# MCU_NAVSS0_UDMASS_ECCAGGR0 register map
Vendor: Texas Instruments
Registers are 32-bit, access not given, reset 0x0 unless marked. A register's access mark holds for its fields unless they carry their own. Offsets are as the file gives them; [hi:lo] are bit positions; {n}, {i} and the like mark numbered series.

## MCU_NAVSS0_UDMASS_ECCAGGR0 (part 2 of 4)
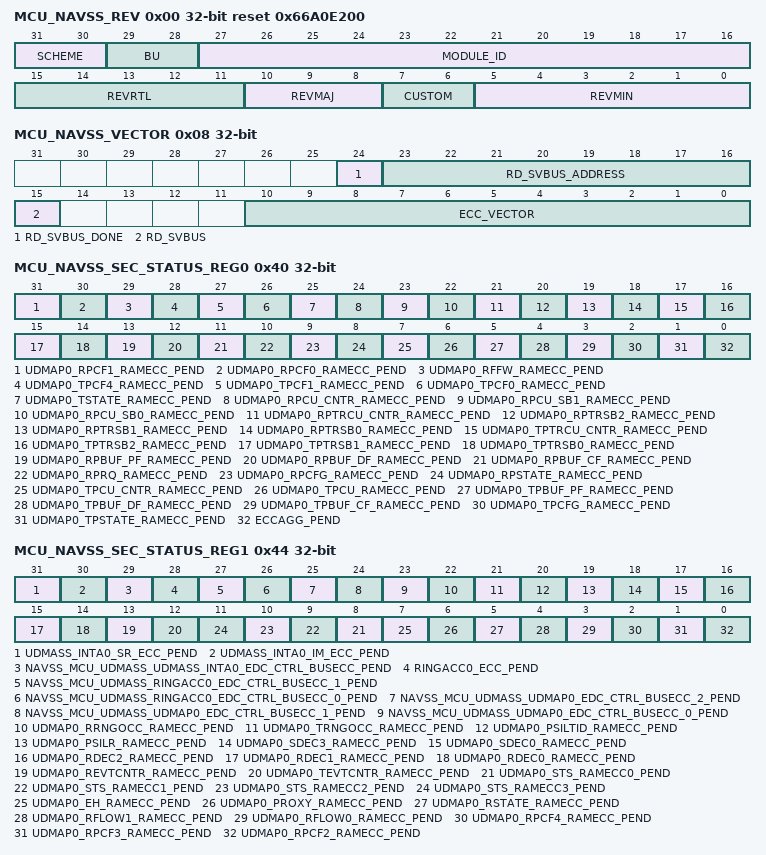
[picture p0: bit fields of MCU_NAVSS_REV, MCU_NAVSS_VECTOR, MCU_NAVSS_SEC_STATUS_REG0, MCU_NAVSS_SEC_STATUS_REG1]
0x00 MCU_NAVSS_REV ro reset 0x66A0E200 — Revision parameters
  [31:30] SCHEME
  [29:28] BU
  [27:16] MODULE_ID
  [15:11] REVRTL — RTL version
  [10:8] REVMAJ — Major version
  [7:6] CUSTOM — Custom version
  [5:0] REVMIN — Minor version
0x08 MCU_NAVSS_VECTOR — ECC Vector Register
  [24] RD_SVBUS_DONE — Status to indicate if read on serial VBUS is complete, write of any value will clear this bit. (access RW1C)
  [23:16] RD_SVBUS_ADDRESS rw — Read address
  [15] RD_SVBUS — Write 1 to trigger a read on the serial VBUS (access RW1S)
  [10:0] ECC_VECTOR rw — Value written to select the corresponding ECC RAM for control or status
0x0C MCU_NAVSS_STAT ro reset 0x78 — Misc Status
  [10:0] NUM_RAMS — Indicates the number of RAMS serviced by the ECC aggregator
0x3C MCU_NAVSS_SEC_EOI_REG — EOI Register The EOI register is used to re-trigger the pulse interrupt signal to ensure that any nested interrupt events are serviced. The software interrupt handler must write to the EOI register at the end of the current interrupt processing routine, so that new events can re-trigger the pulse interrupt signal again. For level interrupt signals the EOI register is not functional and must not be used.
  [0] EOI_WR — EOI Register (access RW1S)
0x40 MCU_NAVSS_SEC_STATUS_REG0 — Interrupt Status Register 0
  [31] UDMAP0_RPCF1_RAMECC_PEND — Interrupt Pending Status for udmap0_rpcf1_ramecc_pend (access RW1S)
  [30] UDMAP0_RPCF0_RAMECC_PEND — Interrupt Pending Status for udmap0_rpcf0_ramecc_pend (access RW1S)
  [29] UDMAP0_RFFW_RAMECC_PEND — Interrupt Pending Status for udmap0_rffw_ramecc_pend (access RW1S)
  [28] UDMAP0_TPCF4_RAMECC_PEND — Interrupt Pending Status for udmap0_tpcf4_ramecc_pend (access RW1S)
  [27] UDMAP0_TPCF1_RAMECC_PEND — Interrupt Pending Status for udmap0_tpcf1_ramecc_pend (access RW1S)
  [26] UDMAP0_TPCF0_RAMECC_PEND — Interrupt Pending Status for udmap0_tpcf0_ramecc_pend (access RW1S)
  [25] UDMAP0_TSTATE_RAMECC_PEND — Interrupt Pending Status for udmap0_tstate_ramecc_pend (access RW1S)
  [24] UDMAP0_RPCU_CNTR_RAMECC_PEND — Interrupt Pending Status for udmap0_rpcu_cntr_ramecc_pend (access RW1S)
  [23] UDMAP0_RPCU_SB1_RAMECC_PEND — Interrupt Pending Status for udmap0_rpcu_sb1_ramecc_pend (access RW1S)
  [22] UDMAP0_RPCU_SB0_RAMECC_PEND — Interrupt Pending Status for udmap0_rpcu_sb0_ramecc_pend (access RW1S)
  [21] UDMAP0_RPTRCU_CNTR_RAMECC_PEND — Interrupt Pending Status for udmap0_rptrcu_cntr_ramecc_pend (access RW1S)
  [20] UDMAP0_RPTRSB2_RAMECC_PEND — Interrupt Pending Status for udmap0_rptrsb2_ramecc_pend (access RW1S)
  [19] UDMAP0_RPTRSB1_RAMECC_PEND — Interrupt Pending Status for udmap0_rptrsb1_ramecc_pend (access RW1S)
  [18] UDMAP0_RPTRSB0_RAMECC_PEND — Interrupt Pending Status for udmap0_rptrsb0_ramecc_pend (access RW1S)
  [17] UDMAP0_TPTRCU_CNTR_RAMECC_PEND — Interrupt Pending Status for udmap0_tptrcu_cntr_ramecc_pend (access RW1S)
  [16] UDMAP0_TPTRSB2_RAMECC_PEND — Interrupt Pending Status for udmap0_tptrsb2_ramecc_pend (access RW1S)
  [15] UDMAP0_TPTRSB1_RAMECC_PEND — Interrupt Pending Status for udmap0_tptrsb1_ramecc_pend (access RW1S)
  [14] UDMAP0_TPTRSB0_RAMECC_PEND — Interrupt Pending Status for udmap0_tptrsb0_ramecc_pend (access RW1S)
  [13] UDMAP0_RPBUF_PF_RAMECC_PEND — Interrupt Pending Status for udmap0_rpbuf_pf_ramecc_pend (access RW1S)
  [12] UDMAP0_RPBUF_DF_RAMECC_PEND — Interrupt Pending Status for udmap0_rpbuf_df_ramecc_pend (access RW1S)
  [11] UDMAP0_RPBUF_CF_RAMECC_PEND — Interrupt Pending Status for udmap0_rpbuf_cf_ramecc_pend (access RW1S)
  [10] UDMAP0_RPRQ_RAMECC_PEND — Interrupt Pending Status for udmap0_rprq_ramecc_pend (access RW1S)
  [9] UDMAP0_RPCFG_RAMECC_PEND — Interrupt Pending Status for udmap0_rpcfg_ramecc_pend (access RW1S)
  [8] UDMAP0_RPSTATE_RAMECC_PEND — Interrupt Pending Status for udmap0_rpstate_ramecc_pend (access RW1S)
  [7] UDMAP0_TPCU_CNTR_RAMECC_PEND — Interrupt Pending Status for udmap0_tpcu_cntr_ramecc_pend (access RW1S)
  [6] UDMAP0_TPCU_RAMECC_PEND — Interrupt Pending Status for udmap0_tpcu_ramecc_pend (access RW1S)
  [5] UDMAP0_TPBUF_PF_RAMECC_PEND — Interrupt Pending Status for udmap0_tpbuf_pf_ramecc_pend (access RW1S)
  [4] UDMAP0_TPBUF_DF_RAMECC_PEND — Interrupt Pending Status for udmap0_tpbuf_df_ramecc_pend (access RW1S)
  [3] UDMAP0_TPBUF_CF_RAMECC_PEND — Interrupt Pending Status for udmap0_tpbuf_cf_ramecc_pend (access RW1S)
  [2] UDMAP0_TPCFG_RAMECC_PEND — Interrupt Pending Status for udmap0_tpcfg_ramecc_pend (access RW1S)
  [1] UDMAP0_TPSTATE_RAMECC_PEND — Interrupt Pending Status for udmap0_tpstate_ramecc_pend (access RW1S)
  [0] ECCAGG_PEND — Interrupt Pending Status for eccagg_pend (access RW1S)
0x44 MCU_NAVSS_SEC_STATUS_REG1 — Interrupt Status Register 1
  [31] UDMASS_INTA0_SR_ECC_PEND — Interrupt Pending Status for udmass_inta0_sr_ecc_pend (access RW1S)
  [30] UDMASS_INTA0_IM_ECC_PEND — Interrupt Pending Status for udmass_inta0_im_ecc_pend (access RW1S)
  [29] NAVSS_MCU_UDMASS_UDMASS_INTA0_EDC_CTRL_BUSECC_PEND — Interrupt Pending Status for navss_mcu_udmass_udmass_inta0_edc_ctrl_busecc_pend (access RW1S)
  [28] RINGACC0_ECC_PEND — Interrupt Pending Status for ringacc0_ecc_pend (access RW1S)
  [27] NAVSS_MCU_UDMASS_RINGACC0_EDC_CTRL_BUSECC_1_PEND — Interrupt Pending Status for navss_mcu_udmass_ringacc0_edc_ctrl_busecc_1_pend (access RW1S)
  [26] NAVSS_MCU_UDMASS_RINGACC0_EDC_CTRL_BUSECC_0_PEND — Interrupt Pending Status for navss_mcu_udmass_ringacc0_edc_ctrl_busecc_0_pend (access RW1S)
  [25] NAVSS_MCU_UDMASS_UDMAP0_EDC_CTRL_BUSECC_2_PEND — Interrupt Pending Status for navss_mcu_udmass_udmap0_edc_ctrl_busecc_2_pend (access RW1S)
  [24] NAVSS_MCU_UDMASS_UDMAP0_EDC_CTRL_BUSECC_1_PEND — Interrupt Pending Status for navss_mcu_udmass_udmap0_edc_ctrl_busecc_1_pend (access RW1S)
  [23] NAVSS_MCU_UDMASS_UDMAP0_EDC_CTRL_BUSECC_0_PEND — Interrupt Pending Status for navss_mcu_udmass_udmap0_edc_ctrl_busecc_0_pend (access RW1S)
  [22] UDMAP0_RRNGOCC_RAMECC_PEND — Interrupt Pending Status for udmap0_rrngocc_ramecc_pend (access RW1S)
  [21] UDMAP0_TRNGOCC_RAMECC_PEND — Interrupt Pending Status for udmap0_trngocc_ramecc_pend (access RW1S)
  [20] UDMAP0_PSILTID_RAMECC_PEND — Interrupt Pending Status for udmap0_psiltid_ramecc_pend (access RW1S)
  [19] UDMAP0_PSILR_RAMECC_PEND — Interrupt Pending Status for udmap0_psilr_ramecc_pend (access RW1S)
  [18] UDMAP0_SDEC3_RAMECC_PEND — Interrupt Pending Status for udmap0_sdec3_ramecc_pend (access RW1S)
  [17] UDMAP0_SDEC0_RAMECC_PEND — Interrupt Pending Status for udmap0_sdec0_ramecc_pend (access RW1S)
  [16] UDMAP0_RDEC2_RAMECC_PEND — Interrupt Pending Status for udmap0_rdec2_ramecc_pend (access RW1S)
  [15] UDMAP0_RDEC1_RAMECC_PEND — Interrupt Pending Status for udmap0_rdec1_ramecc_pend (access RW1S)
  [14] UDMAP0_RDEC0_RAMECC_PEND — Interrupt Pending Status for udmap0_rdec0_ramecc_pend (access RW1S)
  [13] UDMAP0_REVTCNTR_RAMECC_PEND — Interrupt Pending Status for udmap0_revtcntr_ramecc_pend (access RW1S)
  [12] UDMAP0_TEVTCNTR_RAMECC_PEND — Interrupt Pending Status for udmap0_tevtcntr_ramecc_pend (access RW1S)
  [n+8] UDMAP0_STS_RAMECC{n}_PEND (n=0..3) — Interrupt Pending Status for udmap0_sts_ramecc{n}_pend (access RW1S)
  [7] UDMAP0_EH_RAMECC_PEND — Interrupt Pending Status for udmap0_eh_ramecc_pend (access RW1S)
  [6] UDMAP0_PROXY_RAMECC_PEND — Interrupt Pending Status for udmap0_proxy_ramecc_pend (access RW1S)
  [5] UDMAP0_RSTATE_RAMECC_PEND — Interrupt Pending Status for udmap0_rstate_ramecc_pend (access RW1S)
  [4] UDMAP0_RFLOW1_RAMECC_PEND — Interrupt Pending Status for udmap0_rflow1_ramecc_pend (access RW1S)
  [3] UDMAP0_RFLOW0_RAMECC_PEND — Interrupt Pending Status for udmap0_rflow0_ramecc_pend (access RW1S)
  [2] UDMAP0_RPCF4_RAMECC_PEND — Interrupt Pending Status for udmap0_rpcf4_ramecc_pend (access RW1S)
  [1] UDMAP0_RPCF3_RAMECC_PEND — Interrupt Pending Status for udmap0_rpcf3_ramecc_pend (access RW1S)
  [0] UDMAP0_RPCF2_RAMECC_PEND — Interrupt Pending Status for udmap0_rpcf2_ramecc_pend (access RW1S)
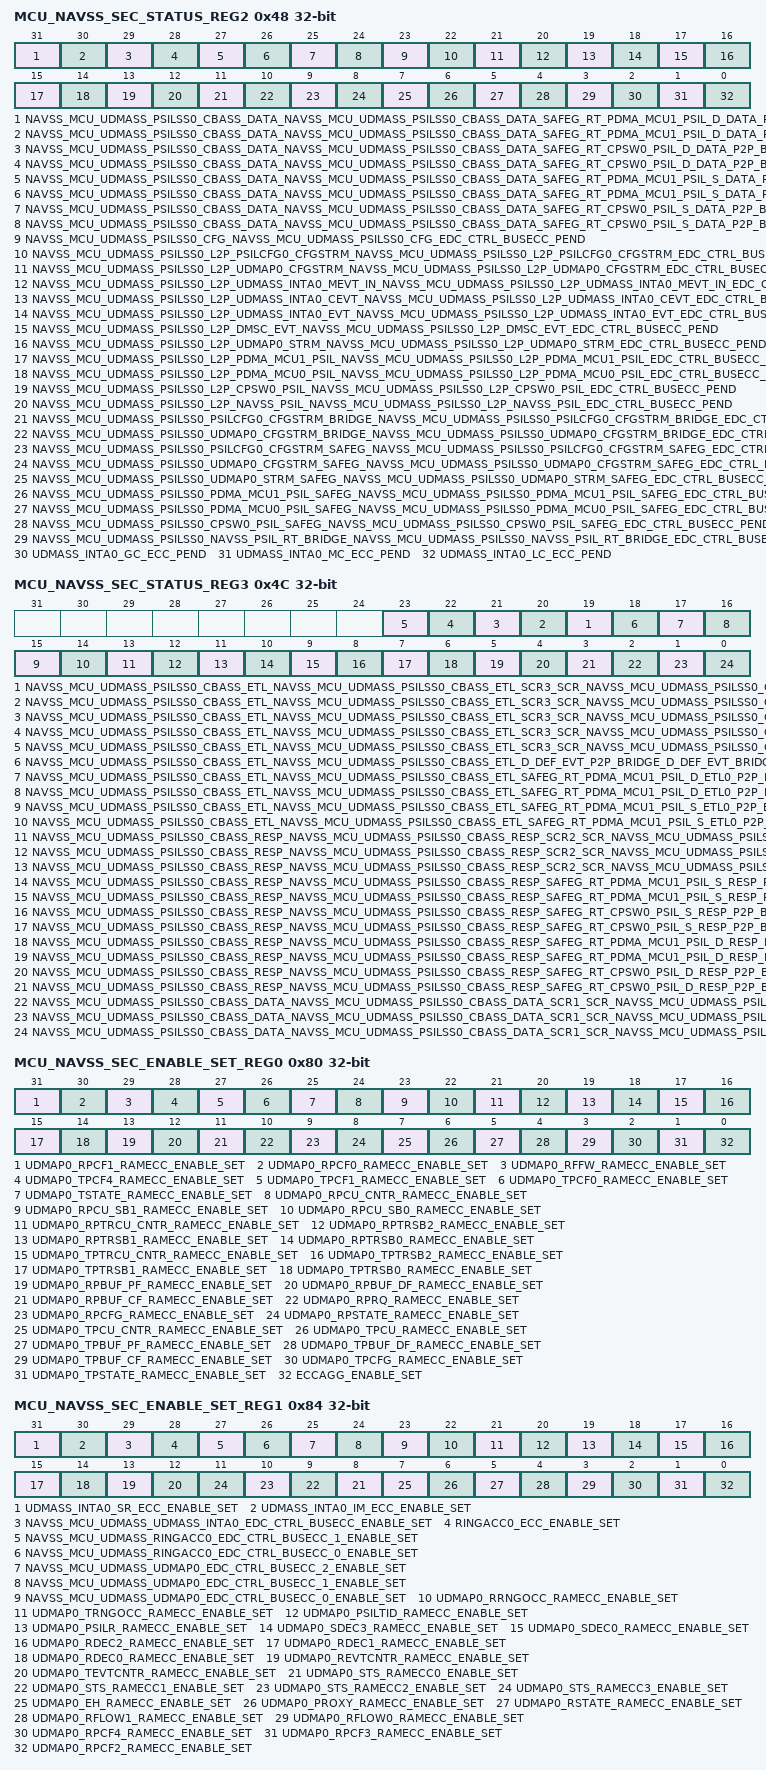
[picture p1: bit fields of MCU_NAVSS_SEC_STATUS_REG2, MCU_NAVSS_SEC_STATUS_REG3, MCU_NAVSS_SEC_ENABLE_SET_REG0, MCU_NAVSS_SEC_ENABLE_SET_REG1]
0x48 MCU_NAVSS_SEC_STATUS_REG2 — Interrupt Status Register 2
  [31] NAVSS_MCU_UDMASS_PSILSS0_CBASS_DATA_NAVSS_MCU_UDMASS_PSILSS0_CBASS_DATA_SAFEG_RT_PDMA_MCU1_PSIL_D_DATA_P2P_BRIDGE_SAFEG_RT_PDMA_MCU1_PSIL_D_DATA_BRIDGE_DST_BUSECC_PEND — Interrupt Pending Status for navss_mcu_udmass_psilss0_cbass_data_navss_mcu_udmass_psilss0_cbass_data_safeg_rt_pdma_mcu1_psil_d_data_p2p_bridge_safeg_rt_pdma_mcu1_psil_d_data_bridge_dst_busecc_pend (access RW1S)
  [30] NAVSS_MCU_UDMASS_PSILSS0_CBASS_DATA_NAVSS_MCU_UDMASS_PSILSS0_CBASS_DATA_SAFEG_RT_PDMA_MCU1_PSIL_D_DATA_P2P_BRIDGE_SAFEG_RT_PDMA_MCU1_PSIL_D_DATA_BRIDGE_SRC_BUSECC_PEND — Interrupt Pending Status for navss_mcu_udmass_psilss0_cbass_data_navss_mcu_udmass_psilss0_cbass_data_safeg_rt_pdma_mcu1_psil_d_data_p2p_bridge_safeg_rt_pdma_mcu1_psil_d_data_bridge_src_busecc_pend (access RW1S)
  [29] NAVSS_MCU_UDMASS_PSILSS0_CBASS_DATA_NAVSS_MCU_UDMASS_PSILSS0_CBASS_DATA_SAFEG_RT_CPSW0_PSIL_D_DATA_P2P_BRIDGE_SAFEG_RT_CPSW0_PSIL_D_DATA_BRIDGE_DST_BUSECC_PEND — Interrupt Pending Status for navss_mcu_udmass_psilss0_cbass_data_navss_mcu_udmass_psilss0_cbass_data_safeg_rt_cpsw0_psil_d_data_p2p_bridge_safeg_rt_cpsw0_psil_d_data_bridge_dst_busecc_pend (access RW1S)
  [28] NAVSS_MCU_UDMASS_PSILSS0_CBASS_DATA_NAVSS_MCU_UDMASS_PSILSS0_CBASS_DATA_SAFEG_RT_CPSW0_PSIL_D_DATA_P2P_BRIDGE_SAFEG_RT_CPSW0_PSIL_D_DATA_BRIDGE_SRC_BUSECC_PEND — Interrupt Pending Status for navss_mcu_udmass_psilss0_cbass_data_navss_mcu_udmass_psilss0_cbass_data_safeg_rt_cpsw0_psil_d_data_p2p_bridge_safeg_rt_cpsw0_psil_d_data_bridge_src_busecc_pend (access RW1S)
  [27] NAVSS_MCU_UDMASS_PSILSS0_CBASS_DATA_NAVSS_MCU_UDMASS_PSILSS0_CBASS_DATA_SAFEG_RT_PDMA_MCU1_PSIL_S_DATA_P2P_BRIDGE_SAFEG_RT_PDMA_MCU1_PSIL_S_DATA_BRIDGE_DST_BUSECC_PEND — Interrupt Pending Status for navss_mcu_udmass_psilss0_cbass_data_navss_mcu_udmass_psilss0_cbass_data_safeg_rt_pdma_mcu1_psil_s_data_p2p_bridge_safeg_rt_pdma_mcu1_psil_s_data_bridge_dst_busecc_pend (access RW1S)
  [26] NAVSS_MCU_UDMASS_PSILSS0_CBASS_DATA_NAVSS_MCU_UDMASS_PSILSS0_CBASS_DATA_SAFEG_RT_PDMA_MCU1_PSIL_S_DATA_P2P_BRIDGE_SAFEG_RT_PDMA_MCU1_PSIL_S_DATA_BRIDGE_SRC_BUSECC_PEND — Interrupt Pending Status for navss_mcu_udmass_psilss0_cbass_data_navss_mcu_udmass_psilss0_cbass_data_safeg_rt_pdma_mcu1_psil_s_data_p2p_bridge_safeg_rt_pdma_mcu1_psil_s_data_bridge_src_busecc_pend (access RW1S)
  [25] NAVSS_MCU_UDMASS_PSILSS0_CBASS_DATA_NAVSS_MCU_UDMASS_PSILSS0_CBASS_DATA_SAFEG_RT_CPSW0_PSIL_S_DATA_P2P_BRIDGE_SAFEG_RT_CPSW0_PSIL_S_DATA_BRIDGE_DST_BUSECC_PEND — Interrupt Pending Status for navss_mcu_udmass_psilss0_cbass_data_navss_mcu_udmass_psilss0_cbass_data_safeg_rt_cpsw0_psil_s_data_p2p_bridge_safeg_rt_cpsw0_psil_s_data_bridge_dst_busecc_pend (access RW1S)
  [24] NAVSS_MCU_UDMASS_PSILSS0_CBASS_DATA_NAVSS_MCU_UDMASS_PSILSS0_CBASS_DATA_SAFEG_RT_CPSW0_PSIL_S_DATA_P2P_BRIDGE_SAFEG_RT_CPSW0_PSIL_S_DATA_BRIDGE_SRC_BUSECC_PEND — Interrupt Pending Status for navss_mcu_udmass_psilss0_cbass_data_navss_mcu_udmass_psilss0_cbass_data_safeg_rt_cpsw0_psil_s_data_p2p_bridge_safeg_rt_cpsw0_psil_s_data_bridge_src_busecc_pend (access RW1S)
  [23] NAVSS_MCU_UDMASS_PSILSS0_CFG_NAVSS_MCU_UDMASS_PSILSS0_CFG_EDC_CTRL_BUSECC_PEND — Interrupt Pending Status for navss_mcu_udmass_psilss0_cfg_navss_mcu_udmass_psilss0_cfg_edc_ctrl_busecc_pend (access RW1S)
  [22] NAVSS_MCU_UDMASS_PSILSS0_L2P_PSILCFG0_CFGSTRM_NAVSS_MCU_UDMASS_PSILSS0_L2P_PSILCFG0_CFGSTRM_EDC_CTRL_BUSECC_PEND — Interrupt Pending Status for navss_mcu_udmass_psilss0_l2p_psilcfg0_cfgstrm_navss_mcu_udmass_psilss0_l2p_psilcfg0_cfgstrm_edc_ctrl_busecc_pend (access RW1S)
  [21] NAVSS_MCU_UDMASS_PSILSS0_L2P_UDMAP0_CFGSTRM_NAVSS_MCU_UDMASS_PSILSS0_L2P_UDMAP0_CFGSTRM_EDC_CTRL_BUSECC_PEND — Interrupt Pending Status for navss_mcu_udmass_psilss0_l2p_udmap0_cfgstrm_navss_mcu_udmass_psilss0_l2p_udmap0_cfgstrm_edc_ctrl_busecc_pend (access RW1S)
  [20] NAVSS_MCU_UDMASS_PSILSS0_L2P_UDMASS_INTA0_MEVT_IN_NAVSS_MCU_UDMASS_PSILSS0_L2P_UDMASS_INTA0_MEVT_IN_EDC_CTRL_BUSECC_PEND — Interrupt Pending Status for navss_mcu_udmass_psilss0_l2p_udmass_inta0_mevt_in_navss_mcu_udmass_psilss0_l2p_udmass_inta0_mevt_in_edc_ctrl_busecc_pend (access RW1S)
  [19] NAVSS_MCU_UDMASS_PSILSS0_L2P_UDMASS_INTA0_CEVT_NAVSS_MCU_UDMASS_PSILSS0_L2P_UDMASS_INTA0_CEVT_EDC_CTRL_BUSECC_PEND — Interrupt Pending Status for navss_mcu_udmass_psilss0_l2p_udmass_inta0_cevt_navss_mcu_udmass_psilss0_l2p_udmass_inta0_cevt_edc_ctrl_busecc_pend (access RW1S)
  [18] NAVSS_MCU_UDMASS_PSILSS0_L2P_UDMASS_INTA0_EVT_NAVSS_MCU_UDMASS_PSILSS0_L2P_UDMASS_INTA0_EVT_EDC_CTRL_BUSECC_PEND — Interrupt Pending Status for navss_mcu_udmass_psilss0_l2p_udmass_inta0_evt_navss_mcu_udmass_psilss0_l2p_udmass_inta0_evt_edc_ctrl_busecc_pend (access RW1S)
  [17] NAVSS_MCU_UDMASS_PSILSS0_L2P_DMSC_EVT_NAVSS_MCU_UDMASS_PSILSS0_L2P_DMSC_EVT_EDC_CTRL_BUSECC_PEND — Interrupt Pending Status for navss_mcu_udmass_psilss0_l2p_dmsc_evt_navss_mcu_udmass_psilss0_l2p_dmsc_evt_edc_ctrl_busecc_pend (access RW1S)
  [16] NAVSS_MCU_UDMASS_PSILSS0_L2P_UDMAP0_STRM_NAVSS_MCU_UDMASS_PSILSS0_L2P_UDMAP0_STRM_EDC_CTRL_BUSECC_PEND — Interrupt Pending Status for navss_mcu_udmass_psilss0_l2p_udmap0_strm_navss_mcu_udmass_psilss0_l2p_udmap0_strm_edc_ctrl_busecc_pend (access RW1S)
  [15] NAVSS_MCU_UDMASS_PSILSS0_L2P_PDMA_MCU1_PSIL_NAVSS_MCU_UDMASS_PSILSS0_L2P_PDMA_MCU1_PSIL_EDC_CTRL_BUSECC_PEND — Interrupt Pending Status for navss_mcu_udmass_psilss0_l2p_pdma_mcu1_psil_navss_mcu_udmass_psilss0_l2p_pdma_mcu1_psil_edc_ctrl_busecc_pend (access RW1S)
  [14] NAVSS_MCU_UDMASS_PSILSS0_L2P_PDMA_MCU0_PSIL_NAVSS_MCU_UDMASS_PSILSS0_L2P_PDMA_MCU0_PSIL_EDC_CTRL_BUSECC_PEND — Interrupt Pending Status for navss_mcu_udmass_psilss0_l2p_pdma_mcu0_psil_navss_mcu_udmass_psilss0_l2p_pdma_mcu0_psil_edc_ctrl_busecc_pend (access RW1S)
  [13] NAVSS_MCU_UDMASS_PSILSS0_L2P_CPSW0_PSIL_NAVSS_MCU_UDMASS_PSILSS0_L2P_CPSW0_PSIL_EDC_CTRL_BUSECC_PEND — Interrupt Pending Status for navss_mcu_udmass_psilss0_l2p_cpsw0_psil_navss_mcu_udmass_psilss0_l2p_cpsw0_psil_edc_ctrl_busecc_pend (access RW1S)
  [12] NAVSS_MCU_UDMASS_PSILSS0_L2P_NAVSS_PSIL_NAVSS_MCU_UDMASS_PSILSS0_L2P_NAVSS_PSIL_EDC_CTRL_BUSECC_PEND — Interrupt Pending Status for navss_mcu_udmass_psilss0_l2p_navss_psil_navss_mcu_udmass_psilss0_l2p_navss_psil_edc_ctrl_busecc_pend (access RW1S)
  [11] NAVSS_MCU_UDMASS_PSILSS0_PSILCFG0_CFGSTRM_BRIDGE_NAVSS_MCU_UDMASS_PSILSS0_PSILCFG0_CFGSTRM_BRIDGE_EDC_CTRL_BUSECC_PEND — Interrupt Pending Status for navss_mcu_udmass_psilss0_psilcfg0_cfgstrm_bridge_navss_mcu_udmass_psilss0_psilcfg0_cfgstrm_bridge_edc_ctrl_busecc_pend (access RW1S)
  [10] NAVSS_MCU_UDMASS_PSILSS0_UDMAP0_CFGSTRM_BRIDGE_NAVSS_MCU_UDMASS_PSILSS0_UDMAP0_CFGSTRM_BRIDGE_EDC_CTRL_BUSECC_PEND — Interrupt Pending Status for navss_mcu_udmass_psilss0_udmap0_cfgstrm_bridge_navss_mcu_udmass_psilss0_udmap0_cfgstrm_bridge_edc_ctrl_busecc_pend (access RW1S)
  [9] NAVSS_MCU_UDMASS_PSILSS0_PSILCFG0_CFGSTRM_SAFEG_NAVSS_MCU_UDMASS_PSILSS0_PSILCFG0_CFGSTRM_SAFEG_EDC_CTRL_BUSECC_PEND — Interrupt Pending Status for navss_mcu_udmass_psilss0_psilcfg0_cfgstrm_safeg_navss_mcu_udmass_psilss0_psilcfg0_cfgstrm_safeg_edc_ctrl_busecc_pend (access RW1S)
  [8] NAVSS_MCU_UDMASS_PSILSS0_UDMAP0_CFGSTRM_SAFEG_NAVSS_MCU_UDMASS_PSILSS0_UDMAP0_CFGSTRM_SAFEG_EDC_CTRL_BUSECC_PEND — Interrupt Pending Status for navss_mcu_udmass_psilss0_udmap0_cfgstrm_safeg_navss_mcu_udmass_psilss0_udmap0_cfgstrm_safeg_edc_ctrl_busecc_pend (access RW1S)
  [7] NAVSS_MCU_UDMASS_PSILSS0_UDMAP0_STRM_SAFEG_NAVSS_MCU_UDMASS_PSILSS0_UDMAP0_STRM_SAFEG_EDC_CTRL_BUSECC_PEND — Interrupt Pending Status for navss_mcu_udmass_psilss0_udmap0_strm_safeg_navss_mcu_udmass_psilss0_udmap0_strm_safeg_edc_ctrl_busecc_pend (access RW1S)
  [6] NAVSS_MCU_UDMASS_PSILSS0_PDMA_MCU1_PSIL_SAFEG_NAVSS_MCU_UDMASS_PSILSS0_PDMA_MCU1_PSIL_SAFEG_EDC_CTRL_BUSECC_PEND — Interrupt Pending Status for navss_mcu_udmass_psilss0_pdma_mcu1_psil_safeg_navss_mcu_udmass_psilss0_pdma_mcu1_psil_safeg_edc_ctrl_busecc_pend (access RW1S)
  [5] NAVSS_MCU_UDMASS_PSILSS0_PDMA_MCU0_PSIL_SAFEG_NAVSS_MCU_UDMASS_PSILSS0_PDMA_MCU0_PSIL_SAFEG_EDC_CTRL_BUSECC_PEND — Interrupt Pending Status for navss_mcu_udmass_psilss0_pdma_mcu0_psil_safeg_navss_mcu_udmass_psilss0_pdma_mcu0_psil_safeg_edc_ctrl_busecc_pend (access RW1S)
  [4] NAVSS_MCU_UDMASS_PSILSS0_CPSW0_PSIL_SAFEG_NAVSS_MCU_UDMASS_PSILSS0_CPSW0_PSIL_SAFEG_EDC_CTRL_BUSECC_PEND — Interrupt Pending Status for navss_mcu_udmass_psilss0_cpsw0_psil_safeg_navss_mcu_udmass_psilss0_cpsw0_psil_safeg_edc_ctrl_busecc_pend (access RW1S)
  [3] NAVSS_MCU_UDMASS_PSILSS0_NAVSS_PSIL_RT_BRIDGE_NAVSS_MCU_UDMASS_PSILSS0_NAVSS_PSIL_RT_BRIDGE_EDC_CTRL_BUSECC_PEND — Interrupt Pending Status for navss_mcu_udmass_psilss0_navss_psil_rt_bridge_navss_mcu_udmass_psilss0_navss_psil_rt_bridge_edc_ctrl_busecc_pend (access RW1S)
  [2] UDMASS_INTA0_GC_ECC_PEND — Interrupt Pending Status for udmass_inta0_gc_ecc_pend (access RW1S)
  [1] UDMASS_INTA0_MC_ECC_PEND — Interrupt Pending Status for udmass_inta0_mc_ecc_pend (access RW1S)
  [0] UDMASS_INTA0_LC_ECC_PEND — Interrupt Pending Status for udmass_inta0_lc_ecc_pend (access RW1S)
0x4C MCU_NAVSS_SEC_STATUS_REG3 — Interrupt Status Register 3
  [n+19] NAVSS_MCU_UDMASS_PSILSS0_CBASS_ETL_NAVSS_MCU_UDMASS_PSILSS0_CBASS_ETL_SCR3_SCR_NAVSS_MCU_UDMASS_PSILSS0_CBASS_ETL_SCR3_SCR_EDC_CTRL_BUSECC_{n}_PEND (n=0..4) — Interrupt Pending Status for navss_mcu_udmass_psilss0_cbass_etl_navss_mcu_udmass_psilss0_cbass_etl_scr3_scr_navss_mcu_udmass_psilss0_cbass_etl_scr3_scr_edc_ctrl_busecc_{n}_pend (access RW1S)
  [18] NAVSS_MCU_UDMASS_PSILSS0_CBASS_ETL_NAVSS_MCU_UDMASS_PSILSS0_CBASS_ETL_D_DEF_EVT_P2P_BRIDGE_D_DEF_EVT_BRIDGE_BUSECC_PEND — Interrupt Pending Status for navss_mcu_udmass_psilss0_cbass_etl_navss_mcu_udmass_psilss0_cbass_etl_d_def_evt_p2p_bridge_d_def_evt_bridge_busecc_pend (access RW1S)
  [17] NAVSS_MCU_UDMASS_PSILSS0_CBASS_ETL_NAVSS_MCU_UDMASS_PSILSS0_CBASS_ETL_SAFEG_RT_PDMA_MCU1_PSIL_D_ETL0_P2P_BRIDGE_SAFEG_RT_PDMA_MCU1_PSIL_D_ETL0_BRIDGE_DST_BUSECC_PEND — Interrupt Pending Status for navss_mcu_udmass_psilss0_cbass_etl_navss_mcu_udmass_psilss0_cbass_etl_safeg_rt_pdma_mcu1_psil_d_etl0_p2p_bridge_safeg_rt_pdma_mcu1_psil_d_etl0_bridge_dst_busecc_pend (access RW1S)
  [16] NAVSS_MCU_UDMASS_PSILSS0_CBASS_ETL_NAVSS_MCU_UDMASS_PSILSS0_CBASS_ETL_SAFEG_RT_PDMA_MCU1_PSIL_D_ETL0_P2P_BRIDGE_SAFEG_RT_PDMA_MCU1_PSIL_D_ETL0_BRIDGE_SRC_BUSECC_PEND — Interrupt Pending Status for navss_mcu_udmass_psilss0_cbass_etl_navss_mcu_udmass_psilss0_cbass_etl_safeg_rt_pdma_mcu1_psil_d_etl0_p2p_bridge_safeg_rt_pdma_mcu1_psil_d_etl0_bridge_src_busecc_pend (access RW1S)
  [15] NAVSS_MCU_UDMASS_PSILSS0_CBASS_ETL_NAVSS_MCU_UDMASS_PSILSS0_CBASS_ETL_SAFEG_RT_PDMA_MCU1_PSIL_S_ETL0_P2P_BRIDGE_SAFEG_RT_PDMA_MCU1_PSIL_S_ETL0_BRIDGE_DST_BUSECC_PEND — Interrupt Pending Status for navss_mcu_udmass_psilss0_cbass_etl_navss_mcu_udmass_psilss0_cbass_etl_safeg_rt_pdma_mcu1_psil_s_etl0_p2p_bridge_safeg_rt_pdma_mcu1_psil_s_etl0_bridge_dst_busecc_pend (access RW1S)
  [14] NAVSS_MCU_UDMASS_PSILSS0_CBASS_ETL_NAVSS_MCU_UDMASS_PSILSS0_CBASS_ETL_SAFEG_RT_PDMA_MCU1_PSIL_S_ETL0_P2P_BRIDGE_SAFEG_RT_PDMA_MCU1_PSIL_S_ETL0_BRIDGE_SRC_BUSECC_PEND — Interrupt Pending Status for navss_mcu_udmass_psilss0_cbass_etl_navss_mcu_udmass_psilss0_cbass_etl_safeg_rt_pdma_mcu1_psil_s_etl0_p2p_bridge_safeg_rt_pdma_mcu1_psil_s_etl0_bridge_src_busecc_pend (access RW1S)
  [13] NAVSS_MCU_UDMASS_PSILSS0_CBASS_RESP_NAVSS_MCU_UDMASS_PSILSS0_CBASS_RESP_SCR2_SCR_NAVSS_MCU_UDMASS_PSILSS0_CBASS_RESP_SCR2_SCR_EDC_CTRL_BUSECC_2_PEND — Interrupt Pending Status for navss_mcu_udmass_psilss0_cbass_resp_navss_mcu_udmass_psilss0_cbass_resp_scr2_scr_navss_mcu_udmass_psilss0_cbass_resp_scr2_scr_edc_ctrl_busecc_2_pend (access RW1S)
  [12] NAVSS_MCU_UDMASS_PSILSS0_CBASS_RESP_NAVSS_MCU_UDMASS_PSILSS0_CBASS_RESP_SCR2_SCR_NAVSS_MCU_UDMASS_PSILSS0_CBASS_RESP_SCR2_SCR_EDC_CTRL_BUSECC_1_PEND — Interrupt Pending Status for navss_mcu_udmass_psilss0_cbass_resp_navss_mcu_udmass_psilss0_cbass_resp_scr2_scr_navss_mcu_udmass_psilss0_cbass_resp_scr2_scr_edc_ctrl_busecc_1_pend (access RW1S)
  [11] NAVSS_MCU_UDMASS_PSILSS0_CBASS_RESP_NAVSS_MCU_UDMASS_PSILSS0_CBASS_RESP_SCR2_SCR_NAVSS_MCU_UDMASS_PSILSS0_CBASS_RESP_SCR2_SCR_EDC_CTRL_BUSECC_0_PEND — Interrupt Pending Status for navss_mcu_udmass_psilss0_cbass_resp_navss_mcu_udmass_psilss0_cbass_resp_scr2_scr_navss_mcu_udmass_psilss0_cbass_resp_scr2_scr_edc_ctrl_busecc_0_pend (access RW1S)
  [10] NAVSS_MCU_UDMASS_PSILSS0_CBASS_RESP_NAVSS_MCU_UDMASS_PSILSS0_CBASS_RESP_SAFEG_RT_PDMA_MCU1_PSIL_S_RESP_P2P_BRIDGE_SAFEG_RT_PDMA_MCU1_PSIL_S_RESP_BRIDGE_DST_BUSECC_PEND — Interrupt Pending Status for navss_mcu_udmass_psilss0_cbass_resp_navss_mcu_udmass_psilss0_cbass_resp_safeg_rt_pdma_mcu1_psil_s_resp_p2p_bridge_safeg_rt_pdma_mcu1_psil_s_resp_bridge_dst_busecc_pend (access RW1S)
  [9] NAVSS_MCU_UDMASS_PSILSS0_CBASS_RESP_NAVSS_MCU_UDMASS_PSILSS0_CBASS_RESP_SAFEG_RT_PDMA_MCU1_PSIL_S_RESP_P2P_BRIDGE_SAFEG_RT_PDMA_MCU1_PSIL_S_RESP_BRIDGE_SRC_BUSECC_PEND — Interrupt Pending Status for navss_mcu_udmass_psilss0_cbass_resp_navss_mcu_udmass_psilss0_cbass_resp_safeg_rt_pdma_mcu1_psil_s_resp_p2p_bridge_safeg_rt_pdma_mcu1_psil_s_resp_bridge_src_busecc_pend (access RW1S)
  [8] NAVSS_MCU_UDMASS_PSILSS0_CBASS_RESP_NAVSS_MCU_UDMASS_PSILSS0_CBASS_RESP_SAFEG_RT_CPSW0_PSIL_S_RESP_P2P_BRIDGE_SAFEG_RT_CPSW0_PSIL_S_RESP_BRIDGE_DST_BUSECC_PEND — Interrupt Pending Status for navss_mcu_udmass_psilss0_cbass_resp_navss_mcu_udmass_psilss0_cbass_resp_safeg_rt_cpsw0_psil_s_resp_p2p_bridge_safeg_rt_cpsw0_psil_s_resp_bridge_dst_busecc_pend (access RW1S)
  [7] NAVSS_MCU_UDMASS_PSILSS0_CBASS_RESP_NAVSS_MCU_UDMASS_PSILSS0_CBASS_RESP_SAFEG_RT_CPSW0_PSIL_S_RESP_P2P_BRIDGE_SAFEG_RT_CPSW0_PSIL_S_RESP_BRIDGE_SRC_BUSECC_PEND — Interrupt Pending Status for navss_mcu_udmass_psilss0_cbass_resp_navss_mcu_udmass_psilss0_cbass_resp_safeg_rt_cpsw0_psil_s_resp_p2p_bridge_safeg_rt_cpsw0_psil_s_resp_bridge_src_busecc_pend (access RW1S)
  [6] NAVSS_MCU_UDMASS_PSILSS0_CBASS_RESP_NAVSS_MCU_UDMASS_PSILSS0_CBASS_RESP_SAFEG_RT_PDMA_MCU1_PSIL_D_RESP_P2P_BRIDGE_SAFEG_RT_PDMA_MCU1_PSIL_D_RESP_BRIDGE_DST_BUSECC_PEND — Interrupt Pending Status for navss_mcu_udmass_psilss0_cbass_resp_navss_mcu_udmass_psilss0_cbass_resp_safeg_rt_pdma_mcu1_psil_d_resp_p2p_bridge_safeg_rt_pdma_mcu1_psil_d_resp_bridge_dst_busecc_pend (access RW1S)
  [5] NAVSS_MCU_UDMASS_PSILSS0_CBASS_RESP_NAVSS_MCU_UDMASS_PSILSS0_CBASS_RESP_SAFEG_RT_PDMA_MCU1_PSIL_D_RESP_P2P_BRIDGE_SAFEG_RT_PDMA_MCU1_PSIL_D_RESP_BRIDGE_SRC_BUSECC_PEND — Interrupt Pending Status for navss_mcu_udmass_psilss0_cbass_resp_navss_mcu_udmass_psilss0_cbass_resp_safeg_rt_pdma_mcu1_psil_d_resp_p2p_bridge_safeg_rt_pdma_mcu1_psil_d_resp_bridge_src_busecc_pend (access RW1S)
  [4] NAVSS_MCU_UDMASS_PSILSS0_CBASS_RESP_NAVSS_MCU_UDMASS_PSILSS0_CBASS_RESP_SAFEG_RT_CPSW0_PSIL_D_RESP_P2P_BRIDGE_SAFEG_RT_CPSW0_PSIL_D_RESP_BRIDGE_DST_BUSECC_PEND — Interrupt Pending Status for navss_mcu_udmass_psilss0_cbass_resp_navss_mcu_udmass_psilss0_cbass_resp_safeg_rt_cpsw0_psil_d_resp_p2p_bridge_safeg_rt_cpsw0_psil_d_resp_bridge_dst_busecc_pend (access RW1S)
  [3] NAVSS_MCU_UDMASS_PSILSS0_CBASS_RESP_NAVSS_MCU_UDMASS_PSILSS0_CBASS_RESP_SAFEG_RT_CPSW0_PSIL_D_RESP_P2P_BRIDGE_SAFEG_RT_CPSW0_PSIL_D_RESP_BRIDGE_SRC_BUSECC_PEND — Interrupt Pending Status for navss_mcu_udmass_psilss0_cbass_resp_navss_mcu_udmass_psilss0_cbass_resp_safeg_rt_cpsw0_psil_d_resp_p2p_bridge_safeg_rt_cpsw0_psil_d_resp_bridge_src_busecc_pend (access RW1S)
  [2] NAVSS_MCU_UDMASS_PSILSS0_CBASS_DATA_NAVSS_MCU_UDMASS_PSILSS0_CBASS_DATA_SCR1_SCR_NAVSS_MCU_UDMASS_PSILSS0_CBASS_DATA_SCR1_SCR_EDC_CTRL_BUSECC_2_PEND — Interrupt Pending Status for navss_mcu_udmass_psilss0_cbass_data_navss_mcu_udmass_psilss0_cbass_data_scr1_scr_navss_mcu_udmass_psilss0_cbass_data_scr1_scr_edc_ctrl_busecc_2_pend (access RW1S)
  [1] NAVSS_MCU_UDMASS_PSILSS0_CBASS_DATA_NAVSS_MCU_UDMASS_PSILSS0_CBASS_DATA_SCR1_SCR_NAVSS_MCU_UDMASS_PSILSS0_CBASS_DATA_SCR1_SCR_EDC_CTRL_BUSECC_1_PEND — Interrupt Pending Status for navss_mcu_udmass_psilss0_cbass_data_navss_mcu_udmass_psilss0_cbass_data_scr1_scr_navss_mcu_udmass_psilss0_cbass_data_scr1_scr_edc_ctrl_busecc_1_pend (access RW1S)
  [0] NAVSS_MCU_UDMASS_PSILSS0_CBASS_DATA_NAVSS_MCU_UDMASS_PSILSS0_CBASS_DATA_SCR1_SCR_NAVSS_MCU_UDMASS_PSILSS0_CBASS_DATA_SCR1_SCR_EDC_CTRL_BUSECC_0_PEND — Interrupt Pending Status for navss_mcu_udmass_psilss0_cbass_data_navss_mcu_udmass_psilss0_cbass_data_scr1_scr_navss_mcu_udmass_psilss0_cbass_data_scr1_scr_edc_ctrl_busecc_0_pend (access RW1S)
0x80 MCU_NAVSS_SEC_ENABLE_SET_REG0 — Interrupt Enable Set Register 0
  [31] UDMAP0_RPCF1_RAMECC_ENABLE_SET — Interrupt Enable Set Register for udmap0_rpcf1_ramecc_pend (access RW1S)
  [30] UDMAP0_RPCF0_RAMECC_ENABLE_SET — Interrupt Enable Set Register for udmap0_rpcf0_ramecc_pend (access RW1S)
  [29] UDMAP0_RFFW_RAMECC_ENABLE_SET — Interrupt Enable Set Register for udmap0_rffw_ramecc_pend (access RW1S)
  [28] UDMAP0_TPCF4_RAMECC_ENABLE_SET — Interrupt Enable Set Register for udmap0_tpcf4_ramecc_pend (access RW1S)
  [27] UDMAP0_TPCF1_RAMECC_ENABLE_SET — Interrupt Enable Set Register for udmap0_tpcf1_ramecc_pend (access RW1S)
  [26] UDMAP0_TPCF0_RAMECC_ENABLE_SET — Interrupt Enable Set Register for udmap0_tpcf0_ramecc_pend (access RW1S)
  [25] UDMAP0_TSTATE_RAMECC_ENABLE_SET — Interrupt Enable Set Register for udmap0_tstate_ramecc_pend (access RW1S)
  [24] UDMAP0_RPCU_CNTR_RAMECC_ENABLE_SET — Interrupt Enable Set Register for udmap0_rpcu_cntr_ramecc_pend (access RW1S)
  [23] UDMAP0_RPCU_SB1_RAMECC_ENABLE_SET — Interrupt Enable Set Register for udmap0_rpcu_sb1_ramecc_pend (access RW1S)
  [22] UDMAP0_RPCU_SB0_RAMECC_ENABLE_SET — Interrupt Enable Set Register for udmap0_rpcu_sb0_ramecc_pend (access RW1S)
  [21] UDMAP0_RPTRCU_CNTR_RAMECC_ENABLE_SET — Interrupt Enable Set Register for udmap0_rptrcu_cntr_ramecc_pend (access RW1S)
  [20] UDMAP0_RPTRSB2_RAMECC_ENABLE_SET — Interrupt Enable Set Register for udmap0_rptrsb2_ramecc_pend (access RW1S)
  [19] UDMAP0_RPTRSB1_RAMECC_ENABLE_SET — Interrupt Enable Set Register for udmap0_rptrsb1_ramecc_pend (access RW1S)
  [18] UDMAP0_RPTRSB0_RAMECC_ENABLE_SET — Interrupt Enable Set Register for udmap0_rptrsb0_ramecc_pend (access RW1S)
  [17] UDMAP0_TPTRCU_CNTR_RAMECC_ENABLE_SET — Interrupt Enable Set Register for udmap0_tptrcu_cntr_ramecc_pend (access RW1S)
  [16] UDMAP0_TPTRSB2_RAMECC_ENABLE_SET — Interrupt Enable Set Register for udmap0_tptrsb2_ramecc_pend (access RW1S)
  [15] UDMAP0_TPTRSB1_RAMECC_ENABLE_SET — Interrupt Enable Set Register for udmap0_tptrsb1_ramecc_pend (access RW1S)
  [14] UDMAP0_TPTRSB0_RAMECC_ENABLE_SET — Interrupt Enable Set Register for udmap0_tptrsb0_ramecc_pend (access RW1S)
  [13] UDMAP0_RPBUF_PF_RAMECC_ENABLE_SET — Interrupt Enable Set Register for udmap0_rpbuf_pf_ramecc_pend (access RW1S)
  [12] UDMAP0_RPBUF_DF_RAMECC_ENABLE_SET — Interrupt Enable Set Register for udmap0_rpbuf_df_ramecc_pend (access RW1S)
  [11] UDMAP0_RPBUF_CF_RAMECC_ENABLE_SET — Interrupt Enable Set Register for udmap0_rpbuf_cf_ramecc_pend (access RW1S)
  [10] UDMAP0_RPRQ_RAMECC_ENABLE_SET — Interrupt Enable Set Register for udmap0_rprq_ramecc_pend (access RW1S)
  [9] UDMAP0_RPCFG_RAMECC_ENABLE_SET — Interrupt Enable Set Register for udmap0_rpcfg_ramecc_pend (access RW1S)
  [8] UDMAP0_RPSTATE_RAMECC_ENABLE_SET — Interrupt Enable Set Register for udmap0_rpstate_ramecc_pend (access RW1S)
  [7] UDMAP0_TPCU_CNTR_RAMECC_ENABLE_SET — Interrupt Enable Set Register for udmap0_tpcu_cntr_ramecc_pend (access RW1S)
  [6] UDMAP0_TPCU_RAMECC_ENABLE_SET — Interrupt Enable Set Register for udmap0_tpcu_ramecc_pend (access RW1S)
  [5] UDMAP0_TPBUF_PF_RAMECC_ENABLE_SET — Interrupt Enable Set Register for udmap0_tpbuf_pf_ramecc_pend (access RW1S)
  [4] UDMAP0_TPBUF_DF_RAMECC_ENABLE_SET — Interrupt Enable Set Register for udmap0_tpbuf_df_ramecc_pend (access RW1S)
  [3] UDMAP0_TPBUF_CF_RAMECC_ENABLE_SET — Interrupt Enable Set Register for udmap0_tpbuf_cf_ramecc_pend (access RW1S)
  [2] UDMAP0_TPCFG_RAMECC_ENABLE_SET — Interrupt Enable Set Register for udmap0_tpcfg_ramecc_pend (access RW1S)
  [1] UDMAP0_TPSTATE_RAMECC_ENABLE_SET — Interrupt Enable Set Register for udmap0_tpstate_ramecc_pend (access RW1S)
  [0] ECCAGG_ENABLE_SET — Interrupt Enable Set Register for eccagg_pend (access RW1S)
0x84 MCU_NAVSS_SEC_ENABLE_SET_REG1 — Interrupt Enable Set Register 1
  [31] UDMASS_INTA0_SR_ECC_ENABLE_SET — Interrupt Enable Set Register for udmass_inta0_sr_ecc_pend (access RW1S)
  [30] UDMASS_INTA0_IM_ECC_ENABLE_SET — Interrupt Enable Set Register for udmass_inta0_im_ecc_pend (access RW1S)
  [29] NAVSS_MCU_UDMASS_UDMASS_INTA0_EDC_CTRL_BUSECC_ENABLE_SET — Interrupt Enable Set Register for navss_mcu_udmass_udmass_inta0_edc_ctrl_busecc_pend (access RW1S)
  [28] RINGACC0_ECC_ENABLE_SET — Interrupt Enable Set Register for ringacc0_ecc_pend (access RW1S)
  [27] NAVSS_MCU_UDMASS_RINGACC0_EDC_CTRL_BUSECC_1_ENABLE_SET — Interrupt Enable Set Register for navss_mcu_udmass_ringacc0_edc_ctrl_busecc_1_pend (access RW1S)
  [26] NAVSS_MCU_UDMASS_RINGACC0_EDC_CTRL_BUSECC_0_ENABLE_SET — Interrupt Enable Set Register for navss_mcu_udmass_ringacc0_edc_ctrl_busecc_0_pend (access RW1S)
  [25] NAVSS_MCU_UDMASS_UDMAP0_EDC_CTRL_BUSECC_2_ENABLE_SET — Interrupt Enable Set Register for navss_mcu_udmass_udmap0_edc_ctrl_busecc_2_pend (access RW1S)
  [24] NAVSS_MCU_UDMASS_UDMAP0_EDC_CTRL_BUSECC_1_ENABLE_SET — Interrupt Enable Set Register for navss_mcu_udmass_udmap0_edc_ctrl_busecc_1_pend (access RW1S)
  [23] NAVSS_MCU_UDMASS_UDMAP0_EDC_CTRL_BUSECC_0_ENABLE_SET — Interrupt Enable Set Register for navss_mcu_udmass_udmap0_edc_ctrl_busecc_0_pend (access RW1S)
  [22] UDMAP0_RRNGOCC_RAMECC_ENABLE_SET — Interrupt Enable Set Register for udmap0_rrngocc_ramecc_pend (access RW1S)
  [21] UDMAP0_TRNGOCC_RAMECC_ENABLE_SET — Interrupt Enable Set Register for udmap0_trngocc_ramecc_pend (access RW1S)
  [20] UDMAP0_PSILTID_RAMECC_ENABLE_SET — Interrupt Enable Set Register for udmap0_psiltid_ramecc_pend (access RW1S)
  [19] UDMAP0_PSILR_RAMECC_ENABLE_SET — Interrupt Enable Set Register for udmap0_psilr_ramecc_pend (access RW1S)
  [18] UDMAP0_SDEC3_RAMECC_ENABLE_SET — Interrupt Enable Set Register for udmap0_sdec3_ramecc_pend (access RW1S)
  [17] UDMAP0_SDEC0_RAMECC_ENABLE_SET — Interrupt Enable Set Register for udmap0_sdec0_ramecc_pend (access RW1S)
  [16] UDMAP0_RDEC2_RAMECC_ENABLE_SET — Interrupt Enable Set Register for udmap0_rdec2_ramecc_pend (access RW1S)
  [15] UDMAP0_RDEC1_RAMECC_ENABLE_SET — Interrupt Enable Set Register for udmap0_rdec1_ramecc_pend (access RW1S)
  [14] UDMAP0_RDEC0_RAMECC_ENABLE_SET — Interrupt Enable Set Register for udmap0_rdec0_ramecc_pend (access RW1S)
  [13] UDMAP0_REVTCNTR_RAMECC_ENABLE_SET — Interrupt Enable Set Register for udmap0_revtcntr_ramecc_pend (access RW1S)
  [12] UDMAP0_TEVTCNTR_RAMECC_ENABLE_SET — Interrupt Enable Set Register for udmap0_tevtcntr_ramecc_pend (access RW1S)
  [n+8] UDMAP0_STS_RAMECC{n}_ENABLE_SET (n=0..3) — Interrupt Enable Set Register for udmap0_sts_ramecc{n}_pend (access RW1S)
  [7] UDMAP0_EH_RAMECC_ENABLE_SET — Interrupt Enable Set Register for udmap0_eh_ramecc_pend (access RW1S)
  [6] UDMAP0_PROXY_RAMECC_ENABLE_SET — Interrupt Enable Set Register for udmap0_proxy_ramecc_pend (access RW1S)
  [5] UDMAP0_RSTATE_RAMECC_ENABLE_SET — Interrupt Enable Set Register for udmap0_rstate_ramecc_pend (access RW1S)
  [4] UDMAP0_RFLOW1_RAMECC_ENABLE_SET — Interrupt Enable Set Register for udmap0_rflow1_ramecc_pend (access RW1S)
  [3] UDMAP0_RFLOW0_RAMECC_ENABLE_SET — Interrupt Enable Set Register for udmap0_rflow0_ramecc_pend (access RW1S)
  [2] UDMAP0_RPCF4_RAMECC_ENABLE_SET — Interrupt Enable Set Register for udmap0_rpcf4_ramecc_pend (access RW1S)
  [1] UDMAP0_RPCF3_RAMECC_ENABLE_SET — Interrupt Enable Set Register for udmap0_rpcf3_ramecc_pend (access RW1S)
  [0] UDMAP0_RPCF2_RAMECC_ENABLE_SET — Interrupt Enable Set Register for udmap0_rpcf2_ramecc_pend (access RW1S)
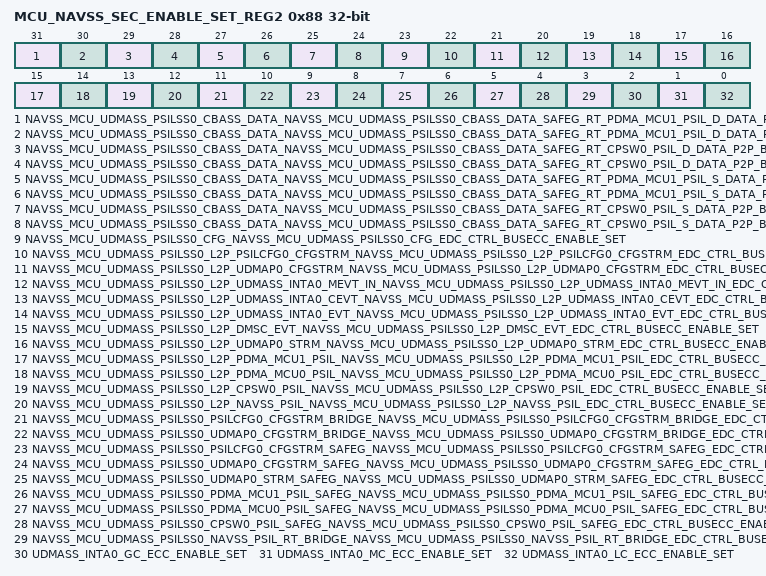
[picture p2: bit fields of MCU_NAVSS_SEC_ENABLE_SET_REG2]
0x88 MCU_NAVSS_SEC_ENABLE_SET_REG2 — Interrupt Enable Set Register 2
  [31] NAVSS_MCU_UDMASS_PSILSS0_CBASS_DATA_NAVSS_MCU_UDMASS_PSILSS0_CBASS_DATA_SAFEG_RT_PDMA_MCU1_PSIL_D_DATA_P2P_BRIDGE_SAFEG_RT_PDMA_MCU1_PSIL_D_DATA_BRIDGE_DST_BUSECC_ENABLE_SET — Interrupt Enable Set Register for navss_mcu_udmass_psilss0_cbass_data_navss_mcu_udmass_psilss0_cbass_data_safeg_rt_pdma_mcu1_psil_d_data_p2p_bridge_safeg_rt_pdma_mcu1_psil_d_data_bridge_dst_busecc_pend (access RW1S)
  [30] NAVSS_MCU_UDMASS_PSILSS0_CBASS_DATA_NAVSS_MCU_UDMASS_PSILSS0_CBASS_DATA_SAFEG_RT_PDMA_MCU1_PSIL_D_DATA_P2P_BRIDGE_SAFEG_RT_PDMA_MCU1_PSIL_D_DATA_BRIDGE_SRC_BUSECC_ENABLE_SET — Interrupt Enable Set Register for navss_mcu_udmass_psilss0_cbass_data_navss_mcu_udmass_psilss0_cbass_data_safeg_rt_pdma_mcu1_psil_d_data_p2p_bridge_safeg_rt_pdma_mcu1_psil_d_data_bridge_src_busecc_pend (access RW1S)
  [29] NAVSS_MCU_UDMASS_PSILSS0_CBASS_DATA_NAVSS_MCU_UDMASS_PSILSS0_CBASS_DATA_SAFEG_RT_CPSW0_PSIL_D_DATA_P2P_BRIDGE_SAFEG_RT_CPSW0_PSIL_D_DATA_BRIDGE_DST_BUSECC_ENABLE_SET — Interrupt Enable Set Register for navss_mcu_udmass_psilss0_cbass_data_navss_mcu_udmass_psilss0_cbass_data_safeg_rt_cpsw0_psil_d_data_p2p_bridge_safeg_rt_cpsw0_psil_d_data_bridge_dst_busecc_pend (access RW1S)
  [28] NAVSS_MCU_UDMASS_PSILSS0_CBASS_DATA_NAVSS_MCU_UDMASS_PSILSS0_CBASS_DATA_SAFEG_RT_CPSW0_PSIL_D_DATA_P2P_BRIDGE_SAFEG_RT_CPSW0_PSIL_D_DATA_BRIDGE_SRC_BUSECC_ENABLE_SET — Interrupt Enable Set Register for navss_mcu_udmass_psilss0_cbass_data_navss_mcu_udmass_psilss0_cbass_data_safeg_rt_cpsw0_psil_d_data_p2p_bridge_safeg_rt_cpsw0_psil_d_data_bridge_src_busecc_pend (access RW1S)
  [27] NAVSS_MCU_UDMASS_PSILSS0_CBASS_DATA_NAVSS_MCU_UDMASS_PSILSS0_CBASS_DATA_SAFEG_RT_PDMA_MCU1_PSIL_S_DATA_P2P_BRIDGE_SAFEG_RT_PDMA_MCU1_PSIL_S_DATA_BRIDGE_DST_BUSECC_ENABLE_SET — Interrupt Enable Set Register for navss_mcu_udmass_psilss0_cbass_data_navss_mcu_udmass_psilss0_cbass_data_safeg_rt_pdma_mcu1_psil_s_data_p2p_bridge_safeg_rt_pdma_mcu1_psil_s_data_bridge_dst_busecc_pend (access RW1S)
  [26] NAVSS_MCU_UDMASS_PSILSS0_CBASS_DATA_NAVSS_MCU_UDMASS_PSILSS0_CBASS_DATA_SAFEG_RT_PDMA_MCU1_PSIL_S_DATA_P2P_BRIDGE_SAFEG_RT_PDMA_MCU1_PSIL_S_DATA_BRIDGE_SRC_BUSECC_ENABLE_SET — Interrupt Enable Set Register for navss_mcu_udmass_psilss0_cbass_data_navss_mcu_udmass_psilss0_cbass_data_safeg_rt_pdma_mcu1_psil_s_data_p2p_bridge_safeg_rt_pdma_mcu1_psil_s_data_bridge_src_busecc_pend (access RW1S)
  [25] NAVSS_MCU_UDMASS_PSILSS0_CBASS_DATA_NAVSS_MCU_UDMASS_PSILSS0_CBASS_DATA_SAFEG_RT_CPSW0_PSIL_S_DATA_P2P_BRIDGE_SAFEG_RT_CPSW0_PSIL_S_DATA_BRIDGE_DST_BUSECC_ENABLE_SET — Interrupt Enable Set Register for navss_mcu_udmass_psilss0_cbass_data_navss_mcu_udmass_psilss0_cbass_data_safeg_rt_cpsw0_psil_s_data_p2p_bridge_safeg_rt_cpsw0_psil_s_data_bridge_dst_busecc_pend (access RW1S)
  [24] NAVSS_MCU_UDMASS_PSILSS0_CBASS_DATA_NAVSS_MCU_UDMASS_PSILSS0_CBASS_DATA_SAFEG_RT_CPSW0_PSIL_S_DATA_P2P_BRIDGE_SAFEG_RT_CPSW0_PSIL_S_DATA_BRIDGE_SRC_BUSECC_ENABLE_SET — Interrupt Enable Set Register for navss_mcu_udmass_psilss0_cbass_data_navss_mcu_udmass_psilss0_cbass_data_safeg_rt_cpsw0_psil_s_data_p2p_bridge_safeg_rt_cpsw0_psil_s_data_bridge_src_busecc_pend (access RW1S)
  [23] NAVSS_MCU_UDMASS_PSILSS0_CFG_NAVSS_MCU_UDMASS_PSILSS0_CFG_EDC_CTRL_BUSECC_ENABLE_SET — Interrupt Enable Set Register for navss_mcu_udmass_psilss0_cfg_navss_mcu_udmass_psilss0_cfg_edc_ctrl_busecc_pend (access RW1S)
  [22] NAVSS_MCU_UDMASS_PSILSS0_L2P_PSILCFG0_CFGSTRM_NAVSS_MCU_UDMASS_PSILSS0_L2P_PSILCFG0_CFGSTRM_EDC_CTRL_BUSECC_ENABLE_SET — Interrupt Enable Set Register for navss_mcu_udmass_psilss0_l2p_psilcfg0_cfgstrm_navss_mcu_udmass_psilss0_l2p_psilcfg0_cfgstrm_edc_ctrl_busecc_pend (access RW1S)
  [21] NAVSS_MCU_UDMASS_PSILSS0_L2P_UDMAP0_CFGSTRM_NAVSS_MCU_UDMASS_PSILSS0_L2P_UDMAP0_CFGSTRM_EDC_CTRL_BUSECC_ENABLE_SET — Interrupt Enable Set Register for navss_mcu_udmass_psilss0_l2p_udmap0_cfgstrm_navss_mcu_udmass_psilss0_l2p_udmap0_cfgstrm_edc_ctrl_busecc_pend (access RW1S)
  [20] NAVSS_MCU_UDMASS_PSILSS0_L2P_UDMASS_INTA0_MEVT_IN_NAVSS_MCU_UDMASS_PSILSS0_L2P_UDMASS_INTA0_MEVT_IN_EDC_CTRL_BUSECC_ENABLE_SET — Interrupt Enable Set Register for navss_mcu_udmass_psilss0_l2p_udmass_inta0_mevt_in_navss_mcu_udmass_psilss0_l2p_udmass_inta0_mevt_in_edc_ctrl_busecc_pend (access RW1S)
  [19] NAVSS_MCU_UDMASS_PSILSS0_L2P_UDMASS_INTA0_CEVT_NAVSS_MCU_UDMASS_PSILSS0_L2P_UDMASS_INTA0_CEVT_EDC_CTRL_BUSECC_ENABLE_SET — Interrupt Enable Set Register for navss_mcu_udmass_psilss0_l2p_udmass_inta0_cevt_navss_mcu_udmass_psilss0_l2p_udmass_inta0_cevt_edc_ctrl_busecc_pend (access RW1S)
  [18] NAVSS_MCU_UDMASS_PSILSS0_L2P_UDMASS_INTA0_EVT_NAVSS_MCU_UDMASS_PSILSS0_L2P_UDMASS_INTA0_EVT_EDC_CTRL_BUSECC_ENABLE_SET — Interrupt Enable Set Register for navss_mcu_udmass_psilss0_l2p_udmass_inta0_evt_navss_mcu_udmass_psilss0_l2p_udmass_inta0_evt_edc_ctrl_busecc_pend (access RW1S)
  [17] NAVSS_MCU_UDMASS_PSILSS0_L2P_DMSC_EVT_NAVSS_MCU_UDMASS_PSILSS0_L2P_DMSC_EVT_EDC_CTRL_BUSECC_ENABLE_SET — Interrupt Enable Set Register for navss_mcu_udmass_psilss0_l2p_dmsc_evt_navss_mcu_udmass_psilss0_l2p_dmsc_evt_edc_ctrl_busecc_pend (access RW1S)
  [16] NAVSS_MCU_UDMASS_PSILSS0_L2P_UDMAP0_STRM_NAVSS_MCU_UDMASS_PSILSS0_L2P_UDMAP0_STRM_EDC_CTRL_BUSECC_ENABLE_SET — Interrupt Enable Set Register for navss_mcu_udmass_psilss0_l2p_udmap0_strm_navss_mcu_udmass_psilss0_l2p_udmap0_strm_edc_ctrl_busecc_pend (access RW1S)
  [15] NAVSS_MCU_UDMASS_PSILSS0_L2P_PDMA_MCU1_PSIL_NAVSS_MCU_UDMASS_PSILSS0_L2P_PDMA_MCU1_PSIL_EDC_CTRL_BUSECC_ENABLE_SET — Interrupt Enable Set Register for navss_mcu_udmass_psilss0_l2p_pdma_mcu1_psil_navss_mcu_udmass_psilss0_l2p_pdma_mcu1_psil_edc_ctrl_busecc_pend (access RW1S)
  [14] NAVSS_MCU_UDMASS_PSILSS0_L2P_PDMA_MCU0_PSIL_NAVSS_MCU_UDMASS_PSILSS0_L2P_PDMA_MCU0_PSIL_EDC_CTRL_BUSECC_ENABLE_SET — Interrupt Enable Set Register for navss_mcu_udmass_psilss0_l2p_pdma_mcu0_psil_navss_mcu_udmass_psilss0_l2p_pdma_mcu0_psil_edc_ctrl_busecc_pend (access RW1S)
  [13] NAVSS_MCU_UDMASS_PSILSS0_L2P_CPSW0_PSIL_NAVSS_MCU_UDMASS_PSILSS0_L2P_CPSW0_PSIL_EDC_CTRL_BUSECC_ENABLE_SET — Interrupt Enable Set Register for navss_mcu_udmass_psilss0_l2p_cpsw0_psil_navss_mcu_udmass_psilss0_l2p_cpsw0_psil_edc_ctrl_busecc_pend (access RW1S)
  [12] NAVSS_MCU_UDMASS_PSILSS0_L2P_NAVSS_PSIL_NAVSS_MCU_UDMASS_PSILSS0_L2P_NAVSS_PSIL_EDC_CTRL_BUSECC_ENABLE_SET — Interrupt Enable Set Register for navss_mcu_udmass_psilss0_l2p_navss_psil_navss_mcu_udmass_psilss0_l2p_navss_psil_edc_ctrl_busecc_pend (access RW1S)
  [11] NAVSS_MCU_UDMASS_PSILSS0_PSILCFG0_CFGSTRM_BRIDGE_NAVSS_MCU_UDMASS_PSILSS0_PSILCFG0_CFGSTRM_BRIDGE_EDC_CTRL_BUSECC_ENABLE_SET — Interrupt Enable Set Register for navss_mcu_udmass_psilss0_psilcfg0_cfgstrm_bridge_navss_mcu_udmass_psilss0_psilcfg0_cfgstrm_bridge_edc_ctrl_busecc_pend (access RW1S)
  [10] NAVSS_MCU_UDMASS_PSILSS0_UDMAP0_CFGSTRM_BRIDGE_NAVSS_MCU_UDMASS_PSILSS0_UDMAP0_CFGSTRM_BRIDGE_EDC_CTRL_BUSECC_ENABLE_SET — Interrupt Enable Set Register for navss_mcu_udmass_psilss0_udmap0_cfgstrm_bridge_navss_mcu_udmass_psilss0_udmap0_cfgstrm_bridge_edc_ctrl_busecc_pend (access RW1S)
  [9] NAVSS_MCU_UDMASS_PSILSS0_PSILCFG0_CFGSTRM_SAFEG_NAVSS_MCU_UDMASS_PSILSS0_PSILCFG0_CFGSTRM_SAFEG_EDC_CTRL_BUSECC_ENABLE_SET — Interrupt Enable Set Register for navss_mcu_udmass_psilss0_psilcfg0_cfgstrm_safeg_navss_mcu_udmass_psilss0_psilcfg0_cfgstrm_safeg_edc_ctrl_busecc_pend (access RW1S)
  [8] NAVSS_MCU_UDMASS_PSILSS0_UDMAP0_CFGSTRM_SAFEG_NAVSS_MCU_UDMASS_PSILSS0_UDMAP0_CFGSTRM_SAFEG_EDC_CTRL_BUSECC_ENABLE_SET — Interrupt Enable Set Register for navss_mcu_udmass_psilss0_udmap0_cfgstrm_safeg_navss_mcu_udmass_psilss0_udmap0_cfgstrm_safeg_edc_ctrl_busecc_pend (access RW1S)
  [7] NAVSS_MCU_UDMASS_PSILSS0_UDMAP0_STRM_SAFEG_NAVSS_MCU_UDMASS_PSILSS0_UDMAP0_STRM_SAFEG_EDC_CTRL_BUSECC_ENABLE_SET — Interrupt Enable Set Register for navss_mcu_udmass_psilss0_udmap0_strm_safeg_navss_mcu_udmass_psilss0_udmap0_strm_safeg_edc_ctrl_busecc_pend (access RW1S)
  [6] NAVSS_MCU_UDMASS_PSILSS0_PDMA_MCU1_PSIL_SAFEG_NAVSS_MCU_UDMASS_PSILSS0_PDMA_MCU1_PSIL_SAFEG_EDC_CTRL_BUSECC_ENABLE_SET — Interrupt Enable Set Register for navss_mcu_udmass_psilss0_pdma_mcu1_psil_safeg_navss_mcu_udmass_psilss0_pdma_mcu1_psil_safeg_edc_ctrl_busecc_pend (access RW1S)
  [5] NAVSS_MCU_UDMASS_PSILSS0_PDMA_MCU0_PSIL_SAFEG_NAVSS_MCU_UDMASS_PSILSS0_PDMA_MCU0_PSIL_SAFEG_EDC_CTRL_BUSECC_ENABLE_SET — Interrupt Enable Set Register for navss_mcu_udmass_psilss0_pdma_mcu0_psil_safeg_navss_mcu_udmass_psilss0_pdma_mcu0_psil_safeg_edc_ctrl_busecc_pend (access RW1S)
  [4] NAVSS_MCU_UDMASS_PSILSS0_CPSW0_PSIL_SAFEG_NAVSS_MCU_UDMASS_PSILSS0_CPSW0_PSIL_SAFEG_EDC_CTRL_BUSECC_ENABLE_SET — Interrupt Enable Set Register for navss_mcu_udmass_psilss0_cpsw0_psil_safeg_navss_mcu_udmass_psilss0_cpsw0_psil_safeg_edc_ctrl_busecc_pend (access RW1S)
  [3] NAVSS_MCU_UDMASS_PSILSS0_NAVSS_PSIL_RT_BRIDGE_NAVSS_MCU_UDMASS_PSILSS0_NAVSS_PSIL_RT_BRIDGE_EDC_CTRL_BUSECC_ENABLE_SET — Interrupt Enable Set Register for navss_mcu_udmass_psilss0_navss_psil_rt_bridge_navss_mcu_udmass_psilss0_navss_psil_rt_bridge_edc_ctrl_busecc_pend (access RW1S)
  [2] UDMASS_INTA0_GC_ECC_ENABLE_SET — Interrupt Enable Set Register for udmass_inta0_gc_ecc_pend (access RW1S)
  [1] UDMASS_INTA0_MC_ECC_ENABLE_SET — Interrupt Enable Set Register for udmass_inta0_mc_ecc_pend (access RW1S)
  [0] UDMASS_INTA0_LC_ECC_ENABLE_SET — Interrupt Enable Set Register for udmass_inta0_lc_ecc_pend (access RW1S)
